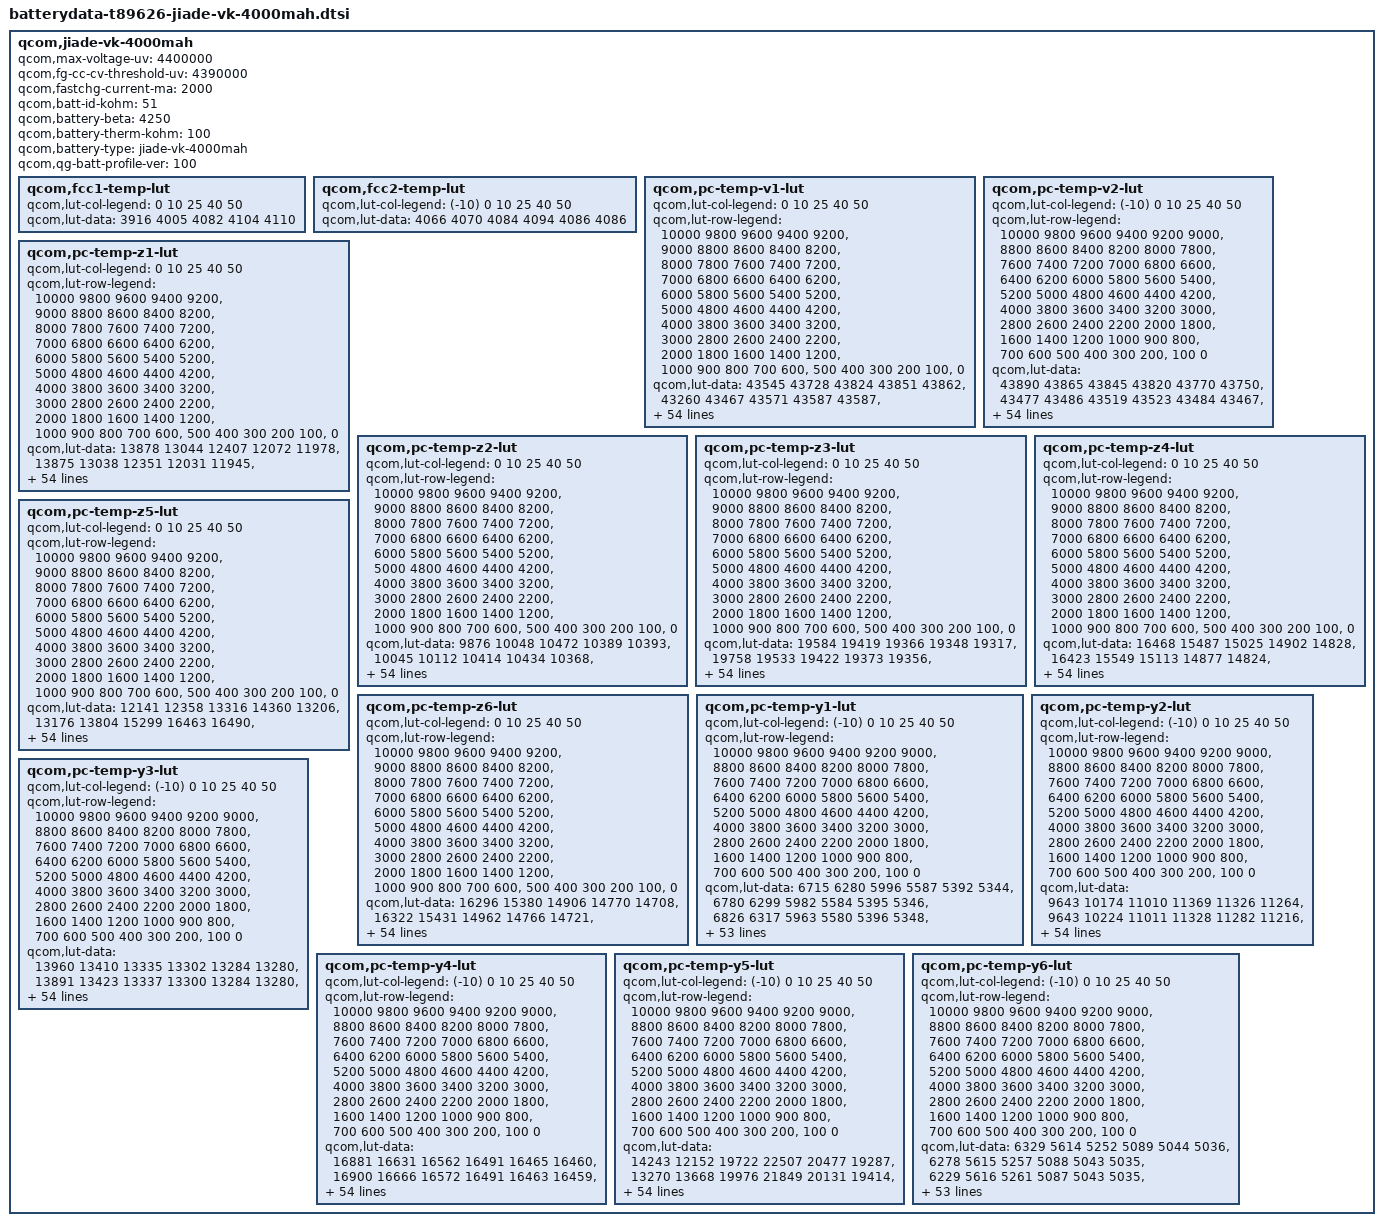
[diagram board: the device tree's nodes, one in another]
qcom,jiade-vk-4000mah {
    /* 3932946_Wingtech_T89626A1_Jiade_4000mAH_PMI632_averaged_MasterSlave_Apr4th2019 */
    qcom,max-voltage-uv = <4400000>;
    qcom,fg-cc-cv-threshold-uv = <4390000>;
    qcom,fastchg-current-ma = <2000>;
    qcom,batt-id-kohm = <51>;
    qcom,battery-beta = <4250>;
    qcom,battery-therm-kohm = <100>;
    qcom,battery-type = "jiade-vk-4000mah";
    qcom,qg-batt-profile-ver = <100>;

	qcom,fcc1-temp-lut {
		qcom,lut-col-legend = <0 10 25 40 50>;
		qcom,lut-data = <3916 4005 4082 4104 4110>;
	};

	qcom,fcc2-temp-lut {
		qcom,lut-col-legend = <(-10) 0 10 25 40 50>;
		qcom,lut-data = <4066 4070 4084 4094 4086 4086>;
	};

	qcom,pc-temp-v1-lut {
		qcom,lut-col-legend = <0 10 25 40 50>;
		qcom,lut-row-legend = <10000 9800 9600 9400 9200>,
			<9000 8800 8600 8400 8200>,
			<8000 7800 7600 7400 7200>,
			<7000 6800 6600 6400 6200>,
			<6000 5800 5600 5400 5200>,
			<5000 4800 4600 4400 4200>,
			<4000 3800 3600 3400 3200>,
			<3000 2800 2600 2400 2200>,
			<2000 1800 1600 1400 1200>,
			<1000 900 800 700 600>,
			<500 400 300 200 100>,
			<0>;
		qcom,lut-data = <43545 43728 43824 43851 43862>,
			<43260 43467 43571 43587 43587>,
			<43002 43204 43320 43346 43350>,
			<42765 42951 43075 43107 43113>,
			<42538 42710 42833 42869 42877>,
			<42313 42475 42593 42630 42639>,
			<42093 42244 42358 42394 42404>,
			<41880 42018 42123 42160 42170>,
			<41670 41798 41893 41930 41939>,
			<41468 41580 41666 41702 41711>,
			<41289 41374 41442 41476 41486>,
			<41121 41196 41232 41255 41266>,
			<40919 41028 41049 41040 41048>,
			<40640 40815 40865 40832 40836>,
			<40356 40524 40631 40626 40631>,
			<40138 40255 40359 40422 40433>,
			<39952 40071 40149 40230 40243>,
			<39802 39921 40003 40057 40066>,
			<39685 39789 39870 39893 39897>,
			<39579 39677 39731 39737 39736>,
			<39463 39556 39587 39590 39588>,
			<39343 39402 39400 39418 39420>,
			<39221 39227 39126 39175 39185>,
			<39096 39033 38892 38937 38946>,
			<38970 38797 38760 38777 38782>,
			<38847 38616 38660 38654 38655>,
			<38723 38531 38567 38545 38544>,
			<38610 38472 38481 38448 38445>,
			<38506 38418 38404 38360 38355>,
			<38413 38372 38330 38280 38272>,
			<38350 38329 38264 38209 38197>,
			<38304 38286 38208 38144 38128>,
			<38268 38245 38160 38089 38067>,
			<38238 38208 38116 38038 38010>,
			<38213 38176 38079 37994 37959>,
			<38185 38143 38042 37952 37911>,
			<38156 38110 38004 37907 37858>,
			<38120 38073 37965 37857 37803>,
			<38070 38020 37912 37796 37736>,
			<38000 37936 37828 37714 37650>,
			<37913 37836 37724 37615 37549>,
			<37791 37721 37613 37507 37440>,
			<37649 37586 37483 37382 37316>,
			<37482 37424 37322 37227 37162>,
			<37348 37269 37169 37077 37015>,
			<37242 37159 37068 36980 36924>,
			<37205 37126 37040 36954 36898>,
			<37174 37103 37019 36934 36878>,
			<37147 37089 37001 36919 36861>,
			<37116 37062 36974 36888 36825>,
			<36992 36923 36808 36699 36622>,
			<36592 36516 36401 36287 36203>,
			<36037 35954 35839 35723 35635>,
			<35282 35192 35073 34954 34856>,
			<34108 34013 33888 33762 33651>,
			<30000 30000 30000 30000 30000>;
	};

	qcom,pc-temp-v2-lut {
		qcom,lut-col-legend = <(-10) 0 10 25 40 50>;
		qcom,lut-row-legend = <10000 9800 9600 9400 9200 9000>,
			<8800 8600 8400 8200 8000 7800>,
			<7600 7400 7200 7000 6800 6600>,
			<6400 6200 6000 5800 5600 5400>,
			<5200 5000 4800 4600 4400 4200>,
			<4000 3800 3600 3400 3200 3000>,
			<2800 2600 2400 2200 2000 1800>,
			<1600 1400 1200 1000 900 800>,
			<700 600 500 400 300 200>,
			<100 0>;
		qcom,lut-data = <43890 43865 43845 43820 43770 43750>,
			<43477 43486 43519 43523 43484 43467>,
			<43105 43144 43215 43243 43213 43198>,
			<42780 42846 42938 42982 42958 42945>,
			<42493 42585 42685 42737 42717 42705>,
			<42236 42333 42439 42497 42480 42470>,
			<42018 42083 42194 42260 42244 42234>,
			<41811 41837 41955 42025 42010 42001>,
			<41562 41577 41723 41795 41780 41771>,
			<41276 41304 41497 41567 41552 41543>,
			<41099 41103 41283 41344 41327 41318>,
			<41037 40991 41089 41125 41107 41099>,
			<40976 40880 40893 40912 40892 40883>,
			<40700 40651 40674 40717 40685 40676>,
			<40098 40298 40441 40530 40483 40473>,
			<39697 40007 40218 40328 40289 40278>,
			<39509 39796 40006 40096 40102 40090>,
			<39353 39605 39806 39886 39922 39911>,
			<39179 39413 39627 39737 39758 39746>,
			<39006 39227 39458 39608 39600 39588>,
			<38843 39044 39268 39435 39420 39410>,
			<38685 38861 39047 39199 39210 39206>,
			<38543 38690 38842 38973 39003 39004>,
			<38421 38530 38677 38782 38804 38806>,
			<38313 38385 38532 38613 38620 38621>,
			<38226 38268 38405 38476 38481 38481>,
			<38155 38169 38293 38363 38373 38371>,
			<38092 38091 38191 38264 38276 38273>,
			<38034 38035 38095 38175 38185 38180>,
			<37982 37989 38009 38096 38102 38096>,
			<37933 37946 37944 38024 38030 38023>,
			<37887 37906 37891 37955 37964 37956>,
			<37843 37868 37849 37893 37903 37894>,
			<37799 37834 37818 37835 37847 37838>,
			<37756 37801 37791 37782 37790 37779>,
			<37706 37765 37761 37733 37716 37696>,
			<37649 37727 37729 37686 37628 37591>,
			<37588 37683 37690 37629 37544 37492>,
			<37522 37626 37639 37557 37465 37404>,
			<37452 37558 37576 37478 37386 37320>,
			<37378 37475 37492 37398 37309 37243>,
			<37299 37373 37382 37308 37224 37162>,
			<37220 37250 37257 37186 37107 37053>,
			<37136 37110 37101 37048 36975 36920>,
			<37050 36976 36941 36907 36842 36787>,
			<36953 36883 36860 36861 36801 36747>,
			<36903 36852 36833 36844 36790 36738>,
			<36848 36823 36805 36825 36778 36727>,
			<36776 36788 36768 36797 36755 36704>,
			<36647 36722 36701 36728 36692 36632>,
			<36397 36539 36495 36470 36430 36341>,
			<35984 36131 36045 35976 35948 35851>,
			<35386 35514 35415 35337 35314 35211>,
			<34517 34646 34537 34461 34453 34342>,
			<33137 33272 33204 33125 33154 33027>,
			<30052 29793 29096 29124 29611 29483>;
	};

	qcom,pc-temp-z1-lut {
		qcom,lut-col-legend = <0 10 25 40 50>;
		qcom,lut-row-legend = <10000 9800 9600 9400 9200>,
			<9000 8800 8600 8400 8200>,
			<8000 7800 7600 7400 7200>,
			<7000 6800 6600 6400 6200>,
			<6000 5800 5600 5400 5200>,
			<5000 4800 4600 4400 4200>,
			<4000 3800 3600 3400 3200>,
			<3000 2800 2600 2400 2200>,
			<2000 1800 1600 1400 1200>,
			<1000 900 800 700 600>,
			<500 400 300 200 100>,
			<0>;
		qcom,lut-data = <13878 13044 12407 12072 11978>,
			<13875 13038 12351 12031 11945>,
			<13873 13016 12331 12014 11938>,
			<13876 12997 12322 12007 11931>,
			<13871 12966 12313 12002 11929>,
			<13838 12937 12301 11999 11928>,
			<13800 12923 12291 11997 11928>,
			<13779 12913 12281 11998 11930>,
			<13766 12908 12274 11999 11934>,
			<13760 12906 12274 12000 11935>,
			<13770 12903 12277 12001 11936>,
			<13788 12898 12280 12001 11936>,
			<13787 12890 12282 12001 11937>,
			<13721 12877 12284 12000 11937>,
			<13655 12846 12276 12000 11938>,
			<13642 12823 12255 11999 11939>,
			<13637 12825 12248 11998 11940>,
			<13628 12834 12255 11999 11941>,
			<13606 12846 12264 12000 11943>,
			<13586 12866 12269 12000 11944>,
			<13589 12883 12273 12001 11945>,
			<13613 12889 12277 12002 11945>,
			<13632 12891 12281 12004 11946>,
			<13644 12891 12284 12007 11947>,
			<13652 12892 12286 12009 11949>,
			<13652 12894 12287 12012 11951>,
			<13648 12896 12289 12014 11953>,
			<13644 12899 12294 12018 11955>,
			<13643 12905 12298 12021 11957>,
			<13646 12924 12301 12024 11960>,
			<13654 12941 12304 12026 11962>,
			<13680 12943 12308 12028 11964>,
			<13700 12942 12312 12031 11966>,
			<13696 12943 12317 12033 11967>,
			<13685 12952 12328 12036 11968>,
			<13689 12963 12339 12039 11969>,
			<13728 12983 12344 12041 11970>,
			<13766 13007 12349 12043 11971>,
			<13770 13012 12354 12046 11972>,
			<13765 13010 12364 12049 11973>,
			<13768 13009 12373 12052 11975>,
			<13808 13027 12374 12054 11977>,
			<13830 13046 12374 12057 11979>,
			<13812 13042 12378 12061 11980>,
			<13825 13040 12386 12065 11982>,
			<13826 13058 12395 12067 11983>,
			<13813 13044 12395 12066 11982>,
			<13828 13049 12398 12067 11982>,
			<13780 13074 12399 12069 11984>,
			<13795 13041 12402 12074 11987>,
			<13807 13080 12416 12081 11993>,
			<13895 13101 12432 12091 12000>,
			<13909 13112 12434 12102 12011>,
			<13876 13158 12456 12121 12026>,
			<13876 13158 12456 12121 12026>,
			<13876 13158 12456 12121 12026>;
	};

	qcom,pc-temp-z2-lut {
		qcom,lut-col-legend = <0 10 25 40 50>;
		qcom,lut-row-legend = <10000 9800 9600 9400 9200>,
			<9000 8800 8600 8400 8200>,
			<8000 7800 7600 7400 7200>,
			<7000 6800 6600 6400 6200>,
			<6000 5800 5600 5400 5200>,
			<5000 4800 4600 4400 4200>,
			<4000 3800 3600 3400 3200>,
			<3000 2800 2600 2400 2200>,
			<2000 1800 1600 1400 1200>,
			<1000 900 800 700 600>,
			<500 400 300 200 100>,
			<0>;
		qcom,lut-data = <9876 10048 10472 10389 10393>,
			<10045 10112 10414 10434 10368>,
			<10081 10200 10430 10484 10422>,
			<10086 10227 10441 10498 10423>,
			<10091 10198 10437 10503 10423>,
			<10115 10163 10410 10487 10424>,
			<10144 10137 10380 10463 10424>,
			<10149 10114 10354 10439 10421>,
			<10142 10100 10333 10414 10412>,
			<10131 10089 10334 10405 10402>,
			<10118 10083 10352 10403 10381>,
			<10099 10088 10367 10404 10359>,
			<10074 10104 10376 10411 10351>,
			<10029 10126 10386 10424 10347>,
			<9990 10164 10398 10436 10347>,
			<9980 10195 10413 10449 10368>,
			<9975 10211 10421 10455 10387>,
			<9975 10225 10422 10429 10390>,
			<9994 10246 10424 10394 10394>,
			<10020 10282 10437 10392 10400>,
			<10031 10315 10466 10403 10412>,
			<10036 10337 10490 10423 10434>,
			<10043 10353 10517 10524 10583>,
			<10055 10349 10532 10627 10754>,
			<10070 10303 10515 10643 10763>,
			<10088 10269 10483 10648 10725>,
			<10112 10296 10474 10642 10664>,
			<10135 10345 10476 10552 10522>,
			<10150 10360 10477 10458 10382>,
			<10164 10362 10466 10423 10321>,
			<10177 10364 10453 10400 10278>,
			<10189 10368 10453 10394 10268>,
			<10201 10375 10458 10393 10276>,
			<10212 10382 10465 10396 10290>,
			<10223 10391 10482 10430 10327>,
			<10237 10402 10504 10487 10389>,
			<10258 10415 10517 10522 10436>,
			<10283 10431 10527 10546 10473>,
			<10310 10449 10540 10568 10511>,
			<10341 10471 10567 10593 10564>,
			<10368 10490 10590 10615 10607>,
			<10390 10500 10596 10628 10595>,
			<10418 10511 10599 10635 10561>,
			<10469 10529 10602 10615 10554>,
			<10257 10654 10626 10600 10547>,
			<10166 10777 10673 10567 10543>,
			<10333 10806 10659 10570 10557>,
			<10422 10842 10670 10574 10543>,
			<10733 11945 10691 10613 10598>,
			<15612 12178 10728 10689 10681>,
			<13163 11985 10722 10626 10591>,
			<15391 11322 10686 10503 10411>,
			<12118 10772 10635 10457 10349>,
			<11915 10678 10558 10383 10269>,
			<11915 10678 10558 10383 10269>,
			<11915 10678 10558 10383 10269>;
	};

	qcom,pc-temp-z3-lut {
		qcom,lut-col-legend = <0 10 25 40 50>;
		qcom,lut-row-legend = <10000 9800 9600 9400 9200>,
			<9000 8800 8600 8400 8200>,
			<8000 7800 7600 7400 7200>,
			<7000 6800 6600 6400 6200>,
			<6000 5800 5600 5400 5200>,
			<5000 4800 4600 4400 4200>,
			<4000 3800 3600 3400 3200>,
			<3000 2800 2600 2400 2200>,
			<2000 1800 1600 1400 1200>,
			<1000 900 800 700 600>,
			<500 400 300 200 100>,
			<0>;
		qcom,lut-data = <19584 19419 19366 19348 19317>,
			<19758 19533 19422 19373 19356>,
			<19802 19598 19448 19391 19366>,
			<19809 19619 19461 19400 19376>,
			<19811 19627 19463 19405 19383>,
			<19800 19631 19463 19409 19390>,
			<19776 19631 19462 19411 19395>,
			<19759 19628 19461 19409 19395>,
			<19748 19625 19458 19404 19392>,
			<19738 19620 19456 19399 19389>,
			<19729 19614 19453 19392 19383>,
			<19720 19598 19448 19387 19377>,
			<19721 19576 19439 19384 19374>,
			<19765 19569 19431 19382 19372>,
			<19810 19574 19434 19380 19371>,
			<19805 19578 19441 19380 19368>,
			<19772 19569 19444 19379 19365>,
			<19736 19549 19436 19373 19360>,
			<19692 19531 19426 19364 19353>,
			<19656 19515 19420 19360 19349>,
			<19651 19507 19416 19358 19344>,
			<19652 19515 19416 19357 19343>,
			<19654 19532 19427 19364 19350>,
			<19664 19538 19436 19374 19363>,
			<19679 19541 19431 19378 19372>,
			<19685 19542 19422 19380 19379>,
			<19687 19541 19422 19384 19383>,
			<19688 19539 19434 19394 19385>,
			<19686 19537 19444 19402 19386>,
			<19682 19535 19447 19401 19383>,
			<19677 19533 19449 19396 19377>,
			<19670 19531 19447 19391 19371>,
			<19661 19530 19441 19386 19367>,
			<19650 19528 19435 19381 19362>,
			<19638 19525 19430 19376 19356>,
			<19626 19520 19426 19371 19349>,
			<19616 19516 19423 19368 19346>,
			<19605 19512 19419 19365 19343>,
			<19594 19508 19416 19364 19342>,
			<19582 19503 19414 19363 19344>,
			<19573 19499 19411 19362 19347>,
			<19568 19494 19408 19361 19347>,
			<19564 19489 19405 19359 19346>,
			<19559 19482 19403 19358 19347>,
			<19360 19460 19399 19356 19348>,
			<19264 19434 19385 19350 19341>,
			<19262 19431 19379 19344 19335>,
			<19261 19420 19377 19341 19329>,
			<19261 19294 19376 19332 19321>,
			<19257 19286 19371 19327 19315>,
			<19259 19299 19370 19341 19333>,
			<19257 19359 19370 19349 19342>,
			<19258 19422 19370 19352 19345>,
			<19261 19422 19364 19352 19348>,
			<19261 19422 19364 19352 19348>,
			<19261 19422 19364 19352 19348>;
	};

	qcom,pc-temp-z4-lut {
		qcom,lut-col-legend = <0 10 25 40 50>;
		qcom,lut-row-legend = <10000 9800 9600 9400 9200>,
			<9000 8800 8600 8400 8200>,
			<8000 7800 7600 7400 7200>,
			<7000 6800 6600 6400 6200>,
			<6000 5800 5600 5400 5200>,
			<5000 4800 4600 4400 4200>,
			<4000 3800 3600 3400 3200>,
			<3000 2800 2600 2400 2200>,
			<2000 1800 1600 1400 1200>,
			<1000 900 800 700 600>,
			<500 400 300 200 100>,
			<0>;
		qcom,lut-data = <16468 15487 15025 14902 14828>,
			<16423 15549 15113 14877 14824>,
			<16311 15424 15076 14906 14855>,
			<16038 15295 14975 14860 14829>,
			<15779 15163 14908 14820 14801>,
			<15621 15052 14860 14792 14778>,
			<15494 14976 14823 14769 14757>,
			<15389 14916 14794 14750 14739>,
			<15303 14872 14771 14733 14722>,
			<15227 14838 14753 14723 14713>,
			<15155 14810 14739 14717 14710>,
			<15087 14783 14727 14712 14707>,
			<15027 14760 14715 14706 14702>,
			<14970 14755 14707 14699 14695>,
			<14925 14761 14710 14694 14691>,
			<14899 14765 14720 14691 14686>,
			<14880 14757 14723 14687 14682>,
			<14864 14740 14701 14685 14679>,
			<14850 14727 14681 14682 14677>,
			<14836 14714 14680 14679 14674>,
			<14818 14707 14680 14675 14671>,
			<14796 14710 14689 14676 14670>,
			<14777 14716 14767 14729 14714>,
			<14760 14736 14826 14787 14769>,
			<14747 14819 14824 14788 14771>,
			<14746 14878 14817 14780 14757>,
			<14755 14868 14804 14768 14744>,
			<14766 14844 14773 14742 14726>,
			<14779 14822 14746 14717 14709>,
			<14791 14799 14731 14707 14701>,
			<14793 14779 14721 14700 14696>,
			<14782 14762 14715 14696 14692>,
			<14768 14748 14712 14693 14687>,
			<14756 14735 14709 14690 14684>,
			<14744 14724 14705 14688 14684>,
			<14734 14714 14702 14686 14683>,
			<14725 14704 14698 14686 14684>,
			<14717 14697 14692 14686 14686>,
			<14712 14695 14690 14687 14688>,
			<14708 14695 14690 14690 14691>,
			<14705 14695 14690 14692 14693>,
			<14703 14689 14684 14687 14690>,
			<14701 14681 14672 14676 14681>,
			<14689 14679 14669 14677 14682>,
			<14846 14670 14662 14674 14681>,
			<14922 14663 14646 14653 14655>,
			<14915 14658 14644 14649 14651>,
			<14910 14662 14636 14639 14642>,
			<14903 14798 14627 14631 14630>,
			<14900 14802 14627 14628 14624>,
			<14897 14791 14639 14636 14636>,
			<14920 14738 14650 14642 14645>,
			<14935 14674 14654 14645 14648>,
			<14950 14684 14669 14649 14648>,
			<14950 14684 14669 14649 14648>,
			<14950 14684 14669 14649 14648>;
	};

	qcom,pc-temp-z5-lut {
		qcom,lut-col-legend = <0 10 25 40 50>;
		qcom,lut-row-legend = <10000 9800 9600 9400 9200>,
			<9000 8800 8600 8400 8200>,
			<8000 7800 7600 7400 7200>,
			<7000 6800 6600 6400 6200>,
			<6000 5800 5600 5400 5200>,
			<5000 4800 4600 4400 4200>,
			<4000 3800 3600 3400 3200>,
			<3000 2800 2600 2400 2200>,
			<2000 1800 1600 1400 1200>,
			<1000 900 800 700 600>,
			<500 400 300 200 100>,
			<0>;
		qcom,lut-data = <12141 12358 13316 14360 13206>,
			<13176 13804 15299 16463 16490>,
			<13653 14936 16462 17037 16795>,
			<13893 15828 17401 17973 17816>,
			<14083 16558 18069 18897 18852>,
			<14264 17290 18555 19798 19963>,
			<14424 18126 19076 20465 21086>,
			<14589 19008 19740 20771 22070>,
			<14795 20008 20468 21029 23021>,
			<15017 21389 21378 21111 23310>,
			<15188 22390 22596 21021 22777>,
			<15347 22373 23102 21047 22250>,
			<15838 21939 22909 21492 22626>,
			<18872 22510 22694 22209 23544>,
			<21864 26458 23870 23060 24144>,
			<21787 29520 27155 24388 24906>,
			<20556 28157 28391 25107 25417>,
			<19326 25277 28194 24323 25055>,
			<18114 24284 28034 23230 24366>,
			<17195 24101 28493 23219 24229>,
			<17374 24047 29839 23748 24348>,
			<18732 31092 31715 24181 24510>,
			<20762 43505 35231 24721 24835>,
			<24890 46294 37507 25203 25163>,
			<30769 44653 32773 24050 24393>,
			<36419 42479 24412 20793 21821>,
			<42511 39462 22879 19792 20732>,
			<46533 35865 24610 21898 21652>,
			<48304 34148 27094 24649 22980>,
			<49513 33244 31238 26707 23889>,
			<49482 32862 35892 28625 24713>,
			<47174 33701 38024 30235 25660>,
			<44056 35432 39274 31656 26985>,
			<40779 36571 40031 32703 27940>,
			<36992 37893 40906 33463 28250>,
			<34449 38699 41643 33987 28435>,
			<32728 39485 41473 33978 28376>,
			<31306 40803 40559 33541 27911>,
			<30002 41159 39508 32910 27535>,
			<28760 40538 38186 31663 27650>,
			<28235 39609 36745 30260 27838>,
			<28433 37916 35335 29518 27545>,
			<29031 35605 34186 29037 27234>,
			<32273 33333 33891 28669 28081>,
			<18748 31187 34033 28784 28799>,
			<11615 27547 31501 28975 28374>,
			<11560 26873 27900 25279 24355>,
			<11559 23494 27757 25682 23653>,
			<11546 12247 29320 23554 23691>,
			<11535 12031 27788 22418 23345>,
			<11577 12415 25322 26392 27663>,
			<11550 16582 21840 24445 24993>,
			<11453 20478 21032 23047 22611>,
			<11385 19068 18432 21003 20883>,
			<11385 19068 18432 21003 20883>,
			<11385 19068 18432 21003 20883>;
	};

	qcom,pc-temp-z6-lut {
		qcom,lut-col-legend = <0 10 25 40 50>;
		qcom,lut-row-legend = <10000 9800 9600 9400 9200>,
			<9000 8800 8600 8400 8200>,
			<8000 7800 7600 7400 7200>,
			<7000 6800 6600 6400 6200>,
			<6000 5800 5600 5400 5200>,
			<5000 4800 4600 4400 4200>,
			<4000 3800 3600 3400 3200>,
			<3000 2800 2600 2400 2200>,
			<2000 1800 1600 1400 1200>,
			<1000 900 800 700 600>,
			<500 400 300 200 100>,
			<0>;
		qcom,lut-data = <16296 15380 14906 14770 14708>,
			<16322 15431 14962 14766 14721>,
			<16294 15394 14951 14783 14737>,
			<16154 15347 14912 14767 14730>,
			<16004 15282 14883 14753 14722>,
			<15907 15222 14860 14743 14716>,
			<15825 15180 14841 14734 14710>,
			<15757 15145 14825 14724 14703>,
			<15700 15117 14813 14716 14695>,
			<15651 15095 14803 14708 14689>,
			<15605 15075 14796 14702 14684>,
			<15562 15051 14788 14697 14680>,
			<15530 15026 14778 14692 14676>,
			<15508 15016 14770 14688 14672>,
			<15488 15012 14771 14685 14669>,
			<15461 15008 14775 14683 14665>,
			<15429 14999 14776 14681 14662>,
			<15399 14983 14764 14676 14658>,
			<15370 14971 14751 14671 14654>,
			<15347 14963 14749 14667 14650>,
			<15339 14958 14748 14664 14646>,
			<15334 14963 14753 14664 14645>,
			<15333 14976 14793 14692 14669>,
			<15336 14995 14824 14722 14700>,
			<15344 15033 14821 14725 14704>,
			<15351 15057 14815 14724 14703>,
			<15360 15054 14809 14722 14702>,
			<15367 15046 14804 14717 14696>,
			<15373 15037 14799 14711 14689>,
			<15378 15028 14795 14706 14684>,
			<15378 15021 14792 14701 14679>,
			<15371 15015 14789 14697 14674>,
			<15363 15010 14784 14693 14670>,
			<15355 15006 14781 14689 14666>,
			<15348 15001 14778 14685 14662>,
			<15345 14998 14776 14682 14658>,
			<15345 14996 14774 14680 14657>,
			<15345 14994 14771 14679 14656>,
			<15344 14994 14770 14679 14656>,
			<15342 14997 14770 14679 14658>,
			<15341 14999 14770 14680 14660>,
			<15346 14999 14767 14678 14659>,
			<15349 14998 14762 14673 14655>,
			<15350 14998 14762 14673 14656>,
			<15333 14991 14759 14672 14656>,
			<15321 14981 14747 14660 14642>,
			<15318 14978 14743 14655 14637>,
			<15319 14974 14739 14649 14630>,
			<15317 14969 14735 14641 14620>,
			<15317 14971 14735 14638 14615>,
			<15323 14980 14742 14650 14630>,
			<15337 14994 14749 14659 14641>,
			<15356 15007 14756 14664 14646>,
			<15382 15026 14766 14670 14652>,
			<15382 15026 14766 14670 14652>,
			<15382 15026 14766 14670 14652>;
	};

	qcom,pc-temp-y1-lut {
		qcom,lut-col-legend = <(-10) 0 10 25 40 50>;
		qcom,lut-row-legend = <10000 9800 9600 9400 9200 9000>,
			<8800 8600 8400 8200 8000 7800>,
			<7600 7400 7200 7000 6800 6600>,
			<6400 6200 6000 5800 5600 5400>,
			<5200 5000 4800 4600 4400 4200>,
			<4000 3800 3600 3400 3200 3000>,
			<2800 2600 2400 2200 2000 1800>,
			<1600 1400 1200 1000 900 800>,
			<700 600 500 400 300 200>,
			<100 0>;
		qcom,lut-data = <6715 6280 5996 5587 5392 5344>,
			<6780 6299 5982 5584 5395 5346>,
			<6826 6317 5963 5580 5396 5348>,
			<6856 6332 5946 5576 5396 5348>,
			<6872 6343 5932 5573 5396 5348>,
			<6876 6346 5927 5571 5396 5348>,
			<6857 6341 5929 5569 5395 5346>,
			<6833 6337 5931 5568 5393 5344>,
			<6835 6340 5933 5566 5392 5344>,
			<6857 6345 5937 5562 5391 5344>,
			<6873 6347 5938 5560 5390 5344>,
			<6881 6341 5930 5560 5390 5343>,
			<6887 6334 5923 5560 5389 5342>,
			<6901 6339 5925 5559 5388 5342>,
			<6932 6358 5931 5557 5388 5342>,
			<6941 6366 5934 5556 5388 5342>,
			<6920 6367 5936 5560 5389 5343>,
			<6894 6367 5938 5562 5389 5343>,
			<6880 6359 5942 5561 5390 5343>,
			<6870 6339 5949 5559 5390 5343>,
			<6866 6334 5951 5560 5391 5343>,
			<6877 6345 5958 5565 5391 5344>,
			<6886 6357 5962 5570 5391 5345>,
			<6873 6363 5956 5572 5393 5345>,
			<6853 6369 5946 5574 5395 5346>,
			<6858 6371 5945 5577 5396 5347>,
			<6885 6369 5952 5581 5397 5349>,
			<6908 6366 5956 5584 5398 5350>,
			<6915 6356 5954 5587 5400 5352>,
			<6915 6343 5950 5588 5402 5353>,
			<6899 6345 5951 5590 5404 5355>,
			<6858 6361 5955 5594 5407 5357>,
			<6837 6368 5956 5596 5410 5359>,
			<6857 6376 5954 5598 5413 5361>,
			<6889 6386 5952 5600 5415 5363>,
			<6896 6382 5958 5601 5417 5364>,
			<6881 6367 5972 5602 5418 5365>,
			<6870 6360 5976 5603 5419 5366>,
			<6873 6370 5968 5609 5420 5367>,
			<6879 6381 5960 5614 5421 5369>,
			<6897 6370 5971 5616 5423 5370>,
			<6929 6342 5985 5619 5425 5370>,
			<6922 6352 5975 5627 5426 5372>,
			<6894 6362 5974 5629 5429 5374>,
			<6925 6378 5998 5636 5436 5378>,
			<6950 6419 6004 5646 5438 5380>,
			<6977 6428 6017 5643 5439 5381>,
			<6921 6432 6013 5657 5441 5379>,
			<6932 6433 6009 5663 5440 5379>,
			<6952 6413 5997 5659 5440 5380>,
			<6981 6434 6018 5662 5441 5382>,
			<6979 6438 6032 5683 5448 5388>,
			<6979 6466 6042 5694 5459 5396>,
			<7137 6503 6083 5723 5474 5406>,
			<7137 6503 6083 5723 5474 5406>,
			<7137 6503 6083 5723 5474 5406>;
	};

	qcom,pc-temp-y2-lut {
		qcom,lut-col-legend = <(-10) 0 10 25 40 50>;
		qcom,lut-row-legend = <10000 9800 9600 9400 9200 9000>,
			<8800 8600 8400 8200 8000 7800>,
			<7600 7400 7200 7000 6800 6600>,
			<6400 6200 6000 5800 5600 5400>,
			<5200 5000 4800 4600 4400 4200>,
			<4000 3800 3600 3400 3200 3000>,
			<2800 2600 2400 2200 2000 1800>,
			<1600 1400 1200 1000 900 800>,
			<700 600 500 400 300 200>,
			<100 0>;
		qcom,lut-data = <9643 10174 11010 11369 11326 11264>,
			<9643 10224 11011 11328 11282 11216>,
			<9643 10286 11003 11288 11237 11161>,
			<9763 10345 10989 11248 11195 11107>,
			<9879 10389 10969 11209 11157 11061>,
			<9979 10405 10945 11171 11124 11031>,
			<10053 10394 10912 11132 11094 11012>,
			<10127 10381 10877 11095 11069 10997>,
			<10263 10392 10857 11061 11050 10986>,
			<10476 10442 10843 11029 11035 10977>,
			<10563 10497 10833 11008 11024 10969>,
			<10541 10591 10819 10992 11002 10958>,
			<10504 10682 10809 10983 10984 10946>,
			<10423 10702 10855 10982 10971 10929>,
			<10263 10708 10978 10984 10940 10903>,
			<10194 10724 11041 10990 10937 10896>,
			<9957 10781 11060 11029 10984 10906>,
			<9714 10850 11075 11084 11046 10924>,
			<9694 10903 11103 11159 11108 10953>,
			<9691 10950 11131 11243 11175 11003>,
			<9687 10980 11133 11271 11234 11078>,
			<9683 11003 11104 11275 11294 11220>,
			<9680 11014 11085 11274 11323 11304>,
			<9679 11005 11113 11279 11296 11265>,
			<9678 10973 11167 11289 11251 11207>,
			<9677 10836 11202 11303 11238 11198>,
			<9676 10228 11229 11327 11244 11206>,
			<9675 9807 11244 11341 11256 11218>,
			<9674 9785 11250 11345 11295 11242>,
			<9672 9773 11253 11349 11339 11278>,
			<9671 9757 11253 11355 11352 11324>,
			<9670 9735 11251 11364 11358 11387>,
			<9668 9718 11246 11368 11368 11429>,
			<9667 9705 11226 11360 11397 11447>,
			<9667 9694 11195 11350 11422 11451>,
			<9665 9686 11160 11347 11396 11418>,
			<9664 9681 11116 11342 11323 11350>,
			<9663 9676 11066 11331 11289 11315>,
			<9662 9671 11011 11300 11283 11287>,
			<9662 9668 10946 11268 11279 11263>,
			<9661 9665 10864 11246 11277 11249>,
			<9661 9663 10768 11225 11277 11242>,
			<9660 9661 10679 11196 11280 11249>,
			<9660 9660 10355 11159 11267 11238>,
			<9659 9659 10039 11137 11222 11197>,
			<9658 9658 9814 11060 11154 11045>,
			<9658 9658 9737 11035 11102 10971>,
			<9658 9657 9699 11001 11100 10990>,
			<9658 9657 9682 10967 11128 11034>,
			<9657 9657 9673 10956 11153 11038>,
			<9657 9656 9669 10936 11098 10982>,
			<9656 9656 9664 10853 11025 10905>,
			<9656 9656 9659 10748 10965 10792>,
			<9653 9655 9657 10697 10858 10673>,
			<9653 9655 9657 10697 10858 10673>,
			<9653 9655 9657 10697 10858 10673>;
	};

	qcom,pc-temp-y3-lut {
		qcom,lut-col-legend = <(-10) 0 10 25 40 50>;
		qcom,lut-row-legend = <10000 9800 9600 9400 9200 9000>,
			<8800 8600 8400 8200 8000 7800>,
			<7600 7400 7200 7000 6800 6600>,
			<6400 6200 6000 5800 5600 5400>,
			<5200 5000 4800 4600 4400 4200>,
			<4000 3800 3600 3400 3200 3000>,
			<2800 2600 2400 2200 2000 1800>,
			<1600 1400 1200 1000 900 800>,
			<700 600 500 400 300 200>,
			<100 0>;
		qcom,lut-data = <13960 13410 13335 13302 13284 13280>,
			<13891 13423 13337 13300 13284 13280>,
			<13807 13433 13339 13299 13284 13280>,
			<13722 13441 13341 13298 13284 13280>,
			<13653 13446 13343 13298 13284 13281>,
			<13614 13447 13345 13298 13284 13281>,
			<13600 13444 13348 13299 13285 13282>,
			<13589 13440 13350 13301 13286 13282>,
			<13565 13441 13352 13302 13286 13283>,
			<13524 13446 13355 13302 13286 13283>,
			<13490 13447 13357 13303 13286 13284>,
			<13463 13416 13361 13306 13287 13285>,
			<13444 13383 13363 13308 13288 13285>,
			<13443 13385 13360 13311 13288 13286>,
			<13444 13397 13351 13315 13288 13286>,
			<13444 13401 13347 13315 13289 13286>,
			<13439 13396 13347 13311 13292 13286>,
			<13432 13388 13346 13307 13294 13286>,
			<13426 13381 13343 13306 13294 13287>,
			<13420 13374 13339 13306 13293 13289>,
			<13415 13366 13334 13305 13293 13289>,
			<13412 13358 13329 13302 13291 13288>,
			<13408 13352 13325 13300 13289 13285>,
			<13397 13349 13323 13298 13285 13282>,
			<13381 13348 13321 13296 13282 13279>,
			<13379 13338 13319 13294 13281 13278>,
			<13385 13298 13318 13293 13281 13278>,
			<13395 13271 13316 13292 13281 13277>,
			<13405 13271 13314 13293 13281 13277>,
			<13417 13274 13312 13294 13280 13276>,
			<13432 13283 13312 13294 13280 13276>,
			<13452 13313 13311 13294 13280 13276>,
			<13475 13338 13311 13294 13281 13277>,
			<13503 13347 13313 13293 13281 13277>,
			<13536 13354 13315 13293 13282 13278>,
			<13570 13368 13317 13293 13282 13278>,
			<13607 13389 13320 13293 13281 13277>,
			<13647 13413 13322 13293 13281 13277>,
			<13693 13442 13324 13292 13281 13277>,
			<13742 13479 13327 13291 13281 13277>,
			<13791 13521 13330 13293 13282 13279>,
			<13843 13573 13333 13295 13283 13280>,
			<13902 13638 13339 13296 13283 13281>,
			<13964 13702 13339 13296 13282 13280>,
			<13992 13720 13334 13292 13278 13276>,
			<14061 13800 13358 13298 13284 13280>,
			<14114 13867 13379 13299 13285 13283>,
			<14178 13921 13404 13302 13289 13286>,
			<14247 13980 13432 13307 13291 13288>,
			<14308 14029 13472 13311 13292 13288>,
			<14382 14069 13509 13310 13289 13284>,
			<14490 14128 13578 13311 13289 13284>,
			<14679 14228 13736 13322 13293 13289>,
			<15304 14356 13937 13336 13299 13295>,
			<15304 14356 13937 13336 13299 13295>,
			<15304 14356 13937 13336 13299 13295>;
	};

	qcom,pc-temp-y4-lut {
		qcom,lut-col-legend = <(-10) 0 10 25 40 50>;
		qcom,lut-row-legend = <10000 9800 9600 9400 9200 9000>,
			<8800 8600 8400 8200 8000 7800>,
			<7600 7400 7200 7000 6800 6600>,
			<6400 6200 6000 5800 5600 5400>,
			<5200 5000 4800 4600 4400 4200>,
			<4000 3800 3600 3400 3200 3000>,
			<2800 2600 2400 2200 2000 1800>,
			<1600 1400 1200 1000 900 800>,
			<700 600 500 400 300 200>,
			<100 0>;
		qcom,lut-data = <16881 16631 16562 16491 16465 16460>,
			<16900 16666 16572 16491 16463 16459>,
			<16915 16702 16590 16492 16462 16458>,
			<16924 16736 16611 16493 16461 16456>,
			<16929 16764 16627 16494 16460 16455>,
			<16931 16785 16632 16494 16460 16454>,
			<16925 16800 16631 16494 16460 16454>,
			<16918 16810 16630 16495 16460 16454>,
			<16925 16805 16632 16496 16461 16455>,
			<16962 16781 16639 16499 16464 16456>,
			<17020 16777 16648 16501 16467 16457>,
			<17221 16973 16660 16503 16469 16459>,
			<17417 17187 16676 16505 16472 16461>,
			<17297 17135 16711 16514 16477 16463>,
			<16905 16938 16765 16532 16483 16467>,
			<16753 16824 16780 16546 16489 16472>,
			<16777 16781 16746 16555 16494 16477>,
			<16802 16752 16713 16567 16500 16484>,
			<16794 16731 16707 16601 16519 16497>,
			<16769 16716 16703 16645 16546 16512>,
			<16744 16694 16690 16647 16552 16518>,
			<16715 16662 16629 16597 16543 16520>,
			<16697 16626 16573 16545 16532 16518>,
			<16699 16584 16547 16507 16501 16494>,
			<16703 16545 16528 16477 16464 16462>,
			<16703 16547 16517 16470 16457 16456>,
			<16701 16608 16510 16467 16457 16456>,
			<16699 16651 16503 16466 16457 16456>,
			<16700 16655 16493 16468 16459 16459>,
			<16702 16657 16485 16471 16464 16464>,
			<16703 16653 16483 16473 16470 16470>,
			<16701 16631 16483 16475 16479 16478>,
			<16700 16619 16484 16476 16486 16486>,
			<16700 16626 16489 16477 16492 16497>,
			<16701 16639 16497 16477 16496 16504>,
			<16702 16650 16507 16477 16489 16497>,
			<16709 16660 16521 16476 16471 16475>,
			<16713 16669 16534 16475 16461 16463>,
			<16715 16680 16549 16471 16458 16459>,
			<16717 16687 16562 16468 16456 16457>,
			<16722 16686 16570 16471 16462 16464>,
			<16732 16683 16575 16478 16470 16474>,
			<16744 16672 16576 16481 16469 16474>,
			<16757 16656 16585 16480 16461 16464>,
			<16747 16636 16576 16464 16442 16437>,
			<16741 16639 16591 16477 16450 16450>,
			<16757 16648 16608 16487 16465 16471>,
			<16777 16665 16631 16508 16489 16500>,
			<16798 16688 16662 16536 16520 16534>,
			<16812 16724 16699 16563 16541 16548>,
			<16808 16737 16716 16549 16491 16482>,
			<16801 16716 16705 16541 16471 16467>,
			<16826 16711 16718 16575 16482 16471>,
			<17088 16742 16759 16634 16520 16501>,
			<17088 16742 16759 16634 16520 16501>,
			<17088 16742 16759 16634 16520 16501>;
	};

	qcom,pc-temp-y5-lut {
		qcom,lut-col-legend = <(-10) 0 10 25 40 50>;
		qcom,lut-row-legend = <10000 9800 9600 9400 9200 9000>,
			<8800 8600 8400 8200 8000 7800>,
			<7600 7400 7200 7000 6800 6600>,
			<6400 6200 6000 5800 5600 5400>,
			<5200 5000 4800 4600 4400 4200>,
			<4000 3800 3600 3400 3200 3000>,
			<2800 2600 2400 2200 2000 1800>,
			<1600 1400 1200 1000 900 800>,
			<700 600 500 400 300 200>,
			<100 0>;
		qcom,lut-data = <14243 12152 19722 22507 20477 19287>,
			<13270 13668 19976 21849 20131 19414>,
			<13032 15307 20277 21067 19730 19448>,
			<13361 16794 20570 20291 19328 19429>,
			<14089 17855 20796 19657 18981 19390>,
			<15059 18216 20899 19298 18745 19371>,
			<17056 18000 20915 19163 18608 19345>,
			<18991 17560 20896 19035 18463 19285>,
			<18379 16893 20741 18638 18105 19096>,
			<15447 15829 20194 17943 17411 18610>,
			<14153 15247 19404 17701 16874 18200>,
			<16508 15160 17599 17951 16568 17934>,
			<19497 15351 16065 18195 16276 17665>,
			<20180 17603 16337 18049 15781 17295>,
			<19695 23020 17453 17550 15182 16809>,
			<19375 24935 18626 16894 15037 16292>,
			<16982 23480 20066 15736 15338 15671>,
			<14527 22114 21443 14968 15593 15196>,
			<14436 22363 22564 15262 15306 14990>,
			<14553 23041 23583 16129 14737 14857>,
			<14558 23271 23967 17709 15121 15151>,
			<14354 23274 24105 21417 18636 17393>,
			<14034 23286 24225 24024 21119 19390>,
			<13432 23815 24439 24786 21179 20170>,
			<12656 24769 24657 25214 21189 20670>,
			<12476 23900 24688 24786 21109 20651>,
			<12510 16925 24632 22910 20740 20105>,
			<12534 12137 24527 21995 20285 19463>,
			<12516 12066 23868 22779 19621 18356>,
			<12487 12040 22777 23871 19036 17302>,
			<12514 12158 21753 24490 19009 17211>,
			<12718 12780 20644 25014 19179 17290>,
			<12994 13285 20260 25154 19521 17459>,
			<13436 13465 20740 24773 21205 18465>,
			<13863 13607 21256 24429 23047 19956>,
			<13898 13879 21229 24717 23629 21528>,
			<13795 14329 20992 25380 23963 23212>,
			<13717 14557 20724 25283 23993 23584>,
			<13691 14615 20333 22903 23265 22561>,
			<13667 14648 19946 21077 22545 21708>,
			<13509 14609 19478 21483 22499 21821>,
			<13219 14522 18941 21942 22507 22258>,
			<13172 14563 18925 21140 21672 23814>,
			<13136 14344 17165 20233 21638 24233>,
			<13401 13739 14725 19614 19372 20873>,
			<13667 13577 14601 20885 20259 18393>,
			<13718 13798 14464 19723 18724 17637>,
			<13894 13888 14257 18733 18148 16848>,
			<14374 14103 14152 18342 17364 16123>,
			<14599 14310 14426 18494 17137 15784>,
			<14598 14427 14519 19295 18248 16599>,
			<14418 14318 14356 19950 21074 17885>,
			<14357 14225 14538 20721 22108 20653>,
			<13069 14283 14363 21661 24638 24745>,
			<13069 14283 14363 21661 24638 24745>,
			<13069 14283 14363 21661 24638 24745>;
	};

	qcom,pc-temp-y6-lut {
		qcom,lut-col-legend = <(-10) 0 10 25 40 50>;
		qcom,lut-row-legend = <10000 9800 9600 9400 9200 9000>,
			<8800 8600 8400 8200 8000 7800>,
			<7600 7400 7200 7000 6800 6600>,
			<6400 6200 6000 5800 5600 5400>,
			<5200 5000 4800 4600 4400 4200>,
			<4000 3800 3600 3400 3200 3000>,
			<2800 2600 2400 2200 2000 1800>,
			<1600 1400 1200 1000 900 800>,
			<700 600 500 400 300 200>,
			<100 0>;
		qcom,lut-data = <6329 5614 5252 5089 5044 5036>,
			<6278 5615 5257 5088 5043 5035>,
			<6229 5616 5261 5087 5043 5035>,
			<6184 5616 5263 5087 5043 5034>,
			<6143 5615 5265 5087 5043 5034>,
			<6108 5614 5265 5087 5043 5035>,
			<6079 5610 5263 5087 5044 5035>,
			<6052 5602 5261 5088 5044 5035>,
			<6022 5592 5261 5089 5045 5036>,
			<5988 5575 5261 5090 5046 5037>,
			<5976 5570 5262 5091 5047 5038>,
			<6008 5599 5266 5092 5048 5038>,
			<6043 5630 5270 5095 5049 5039>,
			<6008 5620 5275 5100 5051 5041>,
			<5897 5581 5283 5107 5053 5042>,
			<5850 5554 5286 5110 5055 5044>,
			<5848 5540 5278 5111 5058 5045>,
			<5847 5529 5269 5113 5061 5047>,
			<5842 5520 5264 5120 5067 5052>,
			<5834 5512 5260 5133 5074 5057>,
			<5829 5503 5251 5133 5075 5059>,
			<5825 5492 5231 5117 5072 5057>,
			<5824 5483 5214 5100 5066 5055>,
			<5824 5477 5206 5088 5055 5046>,
			<5827 5473 5200 5078 5042 5034>,
			<5831 5472 5198 5075 5039 5032>,
			<5840 5475 5197 5074 5039 5032>,
			<5851 5479 5196 5074 5039 5032>,
			<5864 5488 5195 5075 5040 5032>,
			<5878 5503 5195 5077 5041 5034>,
			<5893 5518 5195 5079 5043 5035>,
			<5910 5535 5198 5080 5046 5038>,
			<5931 5555 5202 5080 5048 5041>,
			<5956 5578 5209 5081 5051 5044>,
			<5987 5606 5218 5081 5053 5047>,
			<6020 5640 5228 5082 5051 5045>,
			<6056 5680 5239 5083 5045 5038>,
			<6093 5723 5253 5083 5042 5035>,
			<6133 5772 5271 5082 5042 5034>,
			<6174 5823 5291 5081 5042 5034>,
			<6218 5876 5314 5084 5044 5037>,
			<6264 5930 5342 5089 5048 5041>,
			<6316 5990 5377 5092 5047 5041>,
			<6371 6047 5415 5094 5045 5038>,
			<6404 6067 5418 5088 5037 5028>,
			<6468 6138 5479 5100 5044 5036>,
			<6517 6196 5525 5106 5050 5044>,
			<6577 6244 5577 5116 5059 5054>,
			<6638 6297 5641 5129 5070 5065>,
			<6695 6348 5712 5140 5077 5069>,
			<6757 6387 5781 5138 5060 5047>,
			<6846 6430 5865 5142 5055 5044>,
			<7024 6512 6035 5173 5063 5050>,
			<7671 6633 6231 5215 5080 5065>,
			<7671 6633 6231 5215 5080 5065>,
			<7671 6633 6231 5215 5080 5065>;
	};

};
